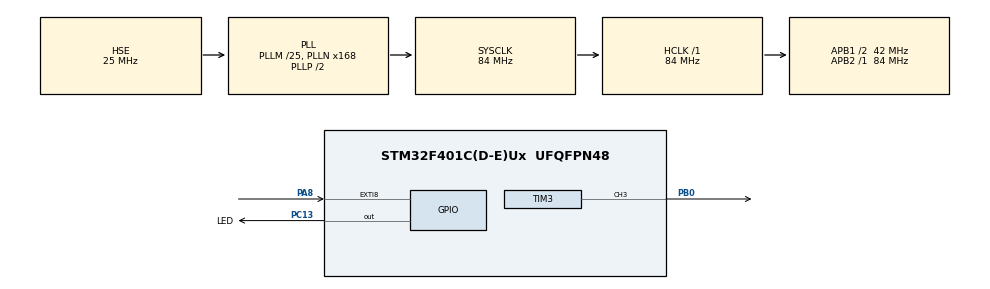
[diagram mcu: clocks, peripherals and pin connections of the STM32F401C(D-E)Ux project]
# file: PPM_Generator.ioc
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Dma.Request0=TIM3_CH3
Dma.TIM3_CH3.0.Direction=DMA_MEMORY_TO_PERIPH
Dma.TIM3_CH3.0.FIFOMode=DMA_FIFOMODE_DISABLE
Dma.TIM3_CH3.0.Instance=DMA1_Stream7
Dma.TIM3_CH3.0.MemDataAlignment=DMA_MDATAALIGN_HALFWORD
Dma.TIM3_CH3.0.MemInc=DMA_MINC_ENABLE
Dma.TIM3_CH3.0.Mode=DMA_CIRCULAR
Dma.TIM3_CH3.0.PeriphDataAlignment=DMA_PDATAALIGN_HALFWORD
Dma.TIM3_CH3.0.PeriphInc=DMA_PINC_DISABLE
Dma.TIM3_CH3.0.Priority=DMA_PRIORITY_VERY_HIGH
Mcu.Family=STM32F4
Mcu.Name=STM32F401C(D-E)Ux
Mcu.Package=UFQFPN48
NVIC.DMA1_Stream7_IRQn=true\:1\:0\:true\:false\:true\:false\:true\:true
NVIC.EXTI9_5_IRQn=true\:2\:0\:true\:false\:true\:true\:true\:true
NVIC.PriorityGroup=NVIC_PRIORITYGROUP_4
PA8.GPIO_ModeDefaultEXTI=GPIO_MODE_IT_FALLING
PA8.Signal=GPXTI8
PB0.Signal=S_TIM3_CH3
PC13-ANTI_TAMP.GPIO_Label=LED
PC13-ANTI_TAMP.Signal=GPIO_Output
PH0\ -\ OSC_IN.Mode=HSE-External-Oscillator
PH0\ -\ OSC_IN.Signal=RCC_OSC_IN
PH1\ -\ OSC_OUT.Mode=HSE-External-Oscillator
PH1\ -\ OSC_OUT.Signal=RCC_OSC_OUT
ProjectManager.HeapSize=0x200
ProjectManager.StackSize=0x400
ProjectManager.TargetToolchain=MDK-ARM V5.32
RCC.48MHZClocksFreq_Value=42000000
RCC.AHBFreq_Value=84000000
RCC.APB1CLKDivider=RCC_HCLK_DIV2
RCC.APB1Freq_Value=42000000
RCC.APB1TimFreq_Value=84000000
RCC.APB2Freq_Value=84000000
RCC.APB2TimFreq_Value=84000000
RCC.CortexFreq_Value=84000000
RCC.HCLKFreq_Value=84000000
RCC.HSE_VALUE=25000000
RCC.HSI_VALUE=16000000
RCC.LSE_VALUE=32768
RCC.PLLM=25
RCC.PLLN=168
RCC.PLLSourceVirtual=RCC_PLLSOURCE_HSE
RCC.SYSCLKFreq_VALUE=84000000
RCC.SYSCLKSource=RCC_SYSCLKSOURCE_PLLCLK
RCC.VCOOutputFreq_Value=168000000
SH.S_TIM3_CH3.0=TIM3_CH3,Output Compare3 CH3
TIM3.Channel-Output\ Compare3\ CH3=TIM_CHANNEL_3
TIM3.OCMode_3=TIM_OCMODE_TOGGLE
TIM3.OCPolarity_3=TIM_OCPOLARITY_LOW
TIM3.Period=19999
TIM3.Prescaler=84-1
TIM4.AutoReloadPreload=TIM_AUTORELOAD_PRELOAD_ENABLE
TIM4.Prescaler=84-1
VP_TIM3_VS_ClockSourceINT.Mode=Internal
VP_TIM4_VS_ClockSourceINT.Mode=Internal
board=custom

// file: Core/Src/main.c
/* USER CODE BEGIN Header */
/**
  ******************************************************************************
  * @file           : main.c
  * @brief          : Main program body
  ******************************************************************************
  * @attention
  *
  * Copyright (c) 2023 STMicroelectronics.
  * All rights reserved.
  *
  * This software is licensed under terms that can be found in the LICENSE file
  * in the root directory of this software component.
  * If no LICENSE file comes with this software, it is provided AS-IS.
  *
  ******************************************************************************
  */
/* USER CODE END Header */
#include "main.h"
#include "dma.h"
#include "tim.h"
#include "gpio.h"

/* USER CODE BEGIN PD */
#define PPM_CHANNEL_NUM 8
#define PPM_WAVE_NUM (PPM_CHANNEL_NUM + 1)*2
#define PPM_CHANNEL_HEADER_WIDTH 400
#define PPM_MAX_WIDTH 19999
#define PPM_CHANNEL_MIN_WIDTH 1000
#define PPM_CHANNEL_MAX_WIDTH 2000

#define CHANNEL_LR 0
#define CHANNEL_FB 1
#define CHANNEL_UD 2
#define CHANNEL_RT 3
#define CHANNEL_APM_MODE 4
#define CHANNEL_CTRL_MODE 5

#define RX_PIN GPIO_PIN_8
/* USER CODE END PD */

/* USER CODE BEGIN PV */
// Rx buffer
uint16_t rx_ppm_pulse_width_us[PPM_CHANNEL_NUM] = {1500, 1500, 1000, 1500, 1000, 1000, 1500, 1500}; // pulse width involve header

// Tx buffer
uint16_t ppm_pulse_width_us[PPM_CHANNEL_NUM] = {1500, 1500, 1000, 1500, 1000, 1000, 1500, 1500}; // pulse width involve header
uint16_t ppm_wave[PPM_WAVE_NUM];

// Run task
uint8_t task_finished_flag = 0;

// Reset states
uint16_t reset_ppm_pulse_width_us[PPM_CHANNEL_NUM] = {1500, 1500, 1000, 1500, 2000, 1000, 1500, 1500};
/* USER CODE END PV */

void SystemClock_Config(void);
/* USER CODE BEGIN PFP */
void ppm_process();
void ppm_set_channel_values_6chs(uint16_t ch1, uint16_t ch2, uint16_t ch3, uint16_t ch4, uint16_t ch5, uint16_t ch6);
void task();
void reset_states();
/* USER CODE END PFP */

int main(void)
{

  /* MCU Configuration--------------------------------------------------------*/

  /* Reset of all peripherals, Initializes the Flash interface and the Systick. */
  HAL_Init();

  /* Configure the system clock */
  SystemClock_Config();

  /* Initialize all configured peripherals */
  MX_GPIO_Init();
  MX_DMA_Init();
  MX_TIM3_Init();
  MX_TIM4_Init();
  /* USER CODE BEGIN 2 */
	ppm_process();
	HAL_TIM_OC_Start_DMA(&htim3, TIM_CHANNEL_3, (uint32_t *)ppm_wave, PPM_WAVE_NUM);
	HAL_TIM_Base_Start(&htim4);
  /* USER CODE END 2 */

  /* Infinite loop */
  /* USER CODE BEGIN WHILE */
  while (1)
  {
		if(rx_ppm_pulse_width_us[CHANNEL_CTRL_MODE] > 1800){	// Run task
			if(task_finished_flag){
				while(1){ // Warning: lower the throttle before push reset button
					if(rx_ppm_pulse_width_us[CHANNEL_CTRL_MODE] <= 1800){
						task_finished_flag = 0;
						break;
					}
					HAL_GPIO_TogglePin(LED_GPIO_Port, LED_Pin);
					HAL_Delay(100);
				}
			}else{
				HAL_GPIO_WritePin(LED_GPIO_Port, LED_Pin, GPIO_PIN_RESET);
				task();
				reset_states();
				task_finished_flag = 1;
			}
		}else{	// Stop/Manual
			HAL_GPIO_WritePin(LED_GPIO_Port, LED_Pin, GPIO_PIN_SET);

			for(int i = 0; i < PPM_CHANNEL_NUM; i++){
				ppm_pulse_width_us[i] = rx_ppm_pulse_width_us[i];
			}
			ppm_process();
		}
		HAL_Delay(20);
    /* USER CODE END WHILE */

  }
}

void SystemClock_Config(void)
{
  RCC_OscInitTypeDef RCC_OscInitStruct = {0};
  RCC_ClkInitTypeDef RCC_ClkInitStruct = {0};

  /** Configure the main internal regulator output voltage
  */
  __HAL_RCC_PWR_CLK_ENABLE();
  __HAL_PWR_VOLTAGESCALING_CONFIG(PWR_REGULATOR_VOLTAGE_SCALE2);

  /** Initializes the RCC Oscillators according to the specified parameters
  * in the RCC_OscInitTypeDef structure.
  */
  RCC_OscInitStruct.OscillatorType = RCC_OSCILLATORTYPE_HSE;
  RCC_OscInitStruct.HSEState = RCC_HSE_ON;
  RCC_OscInitStruct.PLL.PLLState = RCC_PLL_ON;
  RCC_OscInitStruct.PLL.PLLSource = RCC_PLLSOURCE_HSE;
  RCC_OscInitStruct.PLL.PLLM = 25;
  RCC_OscInitStruct.PLL.PLLN = 168;
  RCC_OscInitStruct.PLL.PLLP = RCC_PLLP_DIV2;
  RCC_OscInitStruct.PLL.PLLQ = 4;
  if (HAL_RCC_OscConfig(&RCC_OscInitStruct) != HAL_OK)
  {
    Error_Handler();
  }

  /** Initializes the CPU, AHB and APB buses clocks
  */
  RCC_ClkInitStruct.ClockType = RCC_CLOCKTYPE_HCLK|RCC_CLOCKTYPE_SYSCLK
                              |RCC_CLOCKTYPE_PCLK1|RCC_CLOCKTYPE_PCLK2;
  RCC_ClkInitStruct.SYSCLKSource = RCC_SYSCLKSOURCE_PLLCLK;
  RCC_ClkInitStruct.AHBCLKDivider = RCC_SYSCLK_DIV1;
  RCC_ClkInitStruct.APB1CLKDivider = RCC_HCLK_DIV2;
  RCC_ClkInitStruct.APB2CLKDivider = RCC_HCLK_DIV1;

  if (HAL_RCC_ClockConfig(&RCC_ClkInitStruct, FLASH_LATENCY_2) != HAL_OK)
  {
    Error_Handler();
  }
}

/* USER CODE BEGIN 4 */
void ppm_process(){
	ppm_wave[0] = PPM_CHANNEL_HEADER_WIDTH;
	ppm_wave[1] = ppm_pulse_width_us[0];
	for(int i = 1; i< PPM_CHANNEL_NUM; i++){
		ppm_wave[i*2] = ppm_wave[i*2-1] + PPM_CHANNEL_HEADER_WIDTH;
		ppm_wave[i*2+1] = ppm_wave[i*2-1] + ppm_pulse_width_us[i];
	}
	ppm_wave[PPM_WAVE_NUM - 2] = ppm_wave[PPM_WAVE_NUM - 3] + PPM_CHANNEL_HEADER_WIDTH;
	ppm_wave[PPM_WAVE_NUM - 1] = PPM_MAX_WIDTH;
}

uint8_t channel_index = 0;
uint16_t pulse_width = 0;
void HAL_GPIO_EXTI_Callback(uint16_t GPIO_Pin){ // Detect falling edge
	if(GPIO_Pin == RX_PIN){
		pulse_width = __HAL_TIM_GET_COUNTER(&htim4); // Get timer counts (us)
		__HAL_TIM_SET_COUNTER(&htim4, 0); // Clear timer counts

		if(pulse_width < PPM_CHANNEL_MIN_WIDTH - 200){ // Invalid value
			channel_index = 0;
		}else if(pulse_width > PPM_CHANNEL_MAX_WIDTH + 200){ // Next frame
			channel_index = 0;
		}else if(channel_index < PPM_CHANNEL_NUM){ // Valid value
			rx_ppm_pulse_width_us[channel_index++] = pulse_width;
		}
	}

}

void task(){
	// Launch
	ppm_pulse_width_us[CHANNEL_UD] = 1500;
	ppm_process();
	HAL_Delay(1000);

	ppm_pulse_width_us[CHANNEL_UD] = 1650;
	ppm_process();
	HAL_Delay(2000);

	// Hold
	ppm_pulse_width_us[CHANNEL_UD] = 1500;
	ppm_process();
	HAL_Delay(5000);

	// Land
	ppm_pulse_width_us[CHANNEL_UD] = 1350;
	ppm_process();
	HAL_Delay(3000);

	ppm_pulse_width_us[CHANNEL_UD] = 0;
	ppm_process();
	HAL_Delay(1000);
}

void reset_states(){
	for(int i = 0; i < PPM_CHANNEL_NUM; i++){
		ppm_pulse_width_us[i] = reset_ppm_pulse_width_us[i];
	}
	ppm_process();
}

/* USER CODE END 4 */

void Error_Handler(void)
{
  __disable_irq();
  while (1)
  {
  }
}
